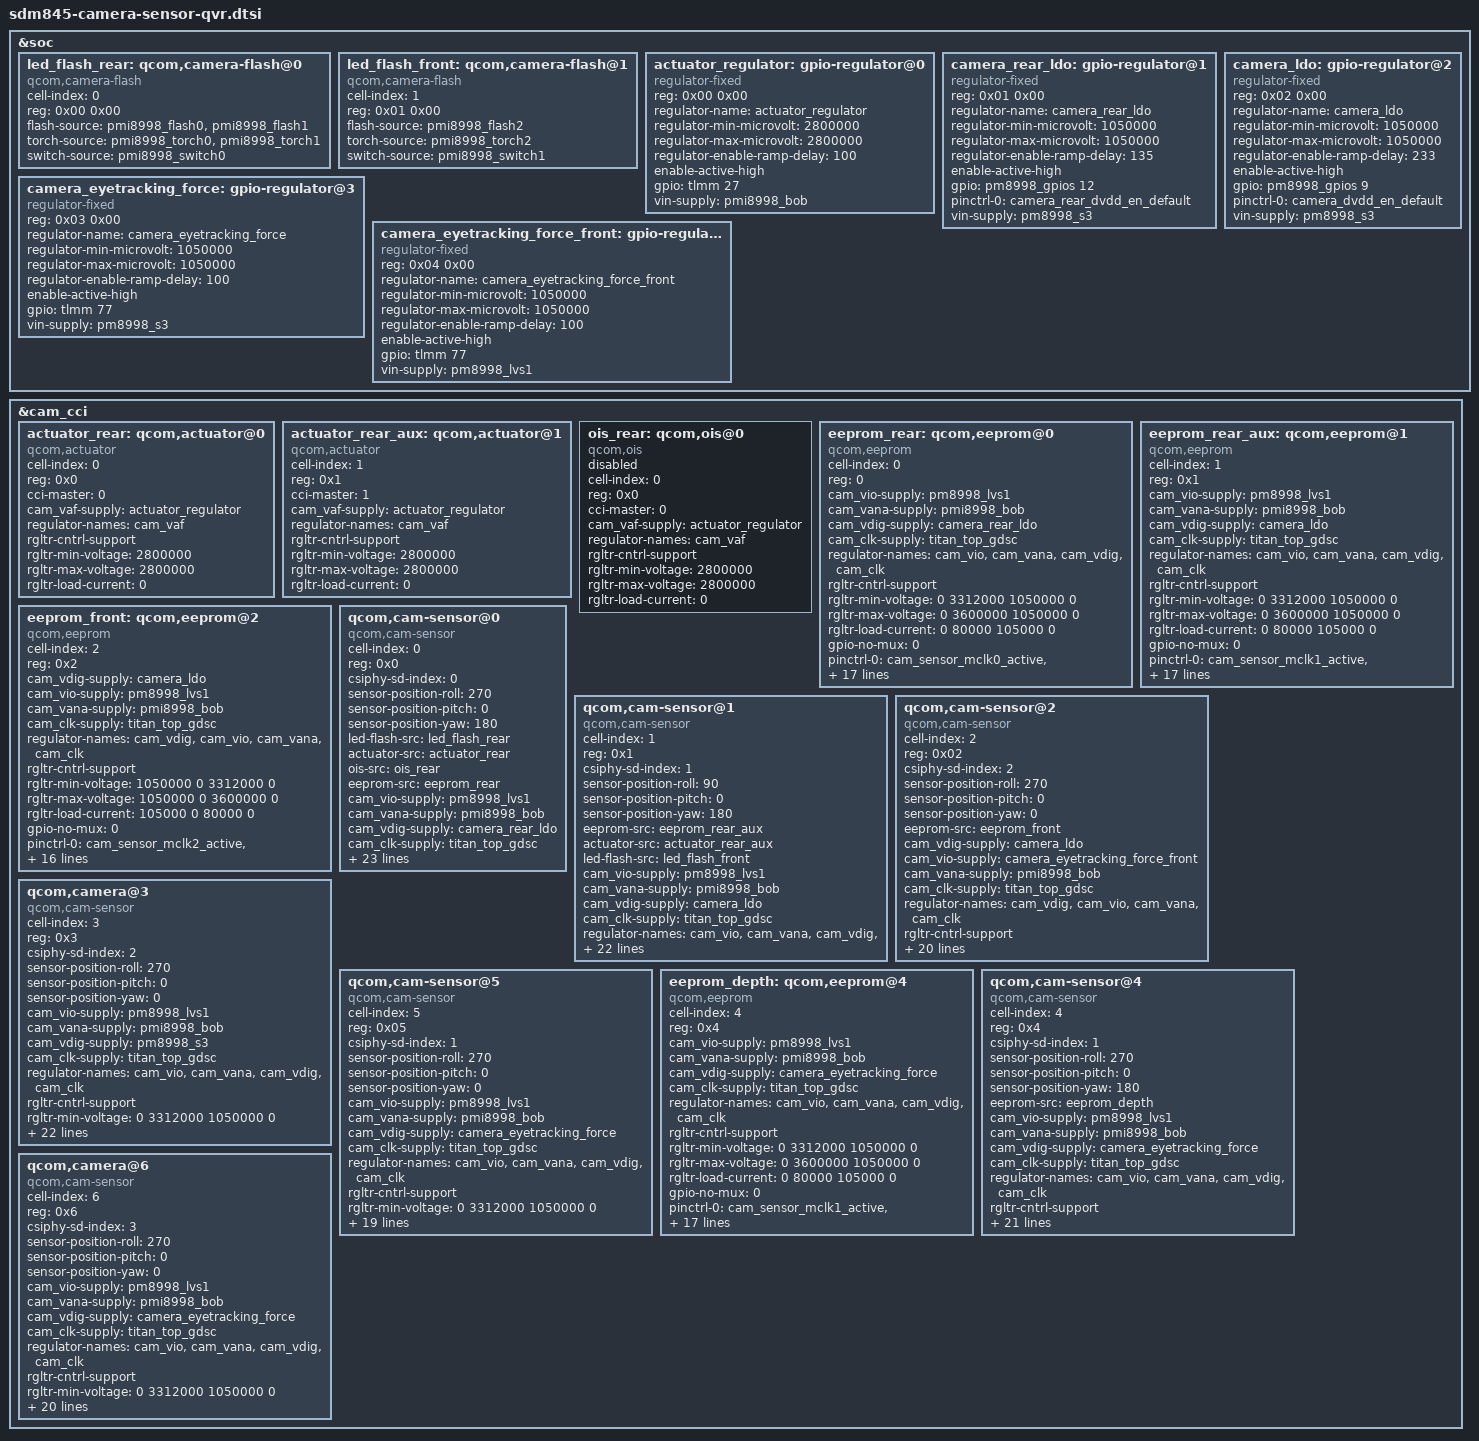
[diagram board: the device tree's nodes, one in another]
/*
 * Copyright (c) 2017-2018, The Linux Foundation. All rights reserved.
 *
 * This program is free software; you can redistribute it and/or modify
 * it under the terms of the GNU General Public License version 2 and
 * only version 2 as published by the Free Software Foundation.
 *
 * This program is distributed in the hope that it will be useful,
 * but WITHOUT ANY WARRANTY; without even the implied warranty of
 * MERCHANTABILITY or FITNESS FOR A PARTICULAR PURPOSE.  See the
 * GNU General Public License for more details.
 */

&soc {
	led_flash_rear: qcom,camera-flash@0 {
		cell-index = <0>;
		reg = <0x00 0x00>;
		compatible = "qcom,camera-flash";
		flash-source = <&pmi8998_flash0 &pmi8998_flash1>;
		torch-source = <&pmi8998_torch0 &pmi8998_torch1>;
		switch-source = <&pmi8998_switch0>;
		status = "ok";
	};

	led_flash_front: qcom,camera-flash@1 {
		cell-index = <1>;
		reg = <0x01 0x00>;
		compatible = "qcom,camera-flash";
		flash-source = <&pmi8998_flash2>;
		torch-source = <&pmi8998_torch2>;
		switch-source = <&pmi8998_switch1>;
		status = "ok";
	};

	actuator_regulator: gpio-regulator@0 {
		compatible = "regulator-fixed";
		reg = <0x00 0x00>;
		regulator-name = "actuator_regulator";
		regulator-min-microvolt = <2800000>;
		regulator-max-microvolt = <2800000>;
		regulator-enable-ramp-delay = <100>;
		enable-active-high;
		gpio = <&tlmm 27 0>;
		vin-supply = <&pmi8998_bob>;
	};

	camera_rear_ldo: gpio-regulator@1 {
		compatible = "regulator-fixed";
		reg = <0x01 0x00>;
		regulator-name = "camera_rear_ldo";
		regulator-min-microvolt = <1050000>;
		regulator-max-microvolt = <1050000>;
		regulator-enable-ramp-delay = <135>;
		enable-active-high;
		gpio = <&pm8998_gpios 12 0>;
		pinctrl-names = "default";
		pinctrl-0 = <&camera_rear_dvdd_en_default>;
		vin-supply = <&pm8998_s3>;
	};

	camera_ldo: gpio-regulator@2 {
		compatible = "regulator-fixed";
		reg = <0x02 0x00>;
		regulator-name = "camera_ldo";
		regulator-min-microvolt = <1050000>;
		regulator-max-microvolt = <1050000>;
		regulator-enable-ramp-delay = <233>;
		enable-active-high;
		gpio = <&pm8998_gpios 9 0>;
		pinctrl-names = "default";
		pinctrl-0 = <&camera_dvdd_en_default>;
		vin-supply = <&pm8998_s3>;
	};

	camera_eyetracking_force: gpio-regulator@3 {
		compatible = "regulator-fixed";
		reg = <0x03 0x00>;
		regulator-name = "camera_eyetracking_force";
		regulator-min-microvolt = <1050000>;
		regulator-max-microvolt = <1050000>;
		regulator-enable-ramp-delay = <100>;
		enable-active-high;
		gpio = <&tlmm 77 0>;
		vin-supply = <&pm8998_s3>;
	};

	camera_eyetracking_force_front: gpio-regulator@4 {
		compatible = "regulator-fixed";
		reg = <0x04 0x00>;
		regulator-name = "camera_eyetracking_force_front";
		regulator-min-microvolt = <1050000>;
		regulator-max-microvolt = <1050000>;
		regulator-enable-ramp-delay = <100>;
		enable-active-high;
		gpio = <&tlmm 77 0>;
		vin-supply = <&pm8998_lvs1>;
	};
};

&cam_cci {
	actuator_rear: qcom,actuator@0 {
		cell-index = <0>;
		reg = <0x0>;
		compatible = "qcom,actuator";
		cci-master = <0>;
		cam_vaf-supply = <&actuator_regulator>;
		regulator-names = "cam_vaf";
		rgltr-cntrl-support;
		rgltr-min-voltage = <2800000>;
		rgltr-max-voltage = <2800000>;
		rgltr-load-current = <0>;
	};

	actuator_rear_aux: qcom,actuator@1 {
		cell-index = <1>;
		reg = <0x1>;
		compatible = "qcom,actuator";
		cci-master = <1>;
		cam_vaf-supply = <&actuator_regulator>;
		regulator-names = "cam_vaf";
		rgltr-cntrl-support;
		rgltr-min-voltage = <2800000>;
		rgltr-max-voltage = <2800000>;
		rgltr-load-current = <0>;
	};

	ois_rear: qcom,ois@0 {
		cell-index = <0>;
		reg = <0x0>;
		compatible = "qcom,ois";
		cci-master = <0>;
		cam_vaf-supply = <&actuator_regulator>;
		regulator-names = "cam_vaf";
		rgltr-cntrl-support;
		rgltr-min-voltage = <2800000>;
		rgltr-max-voltage = <2800000>;
		rgltr-load-current = <0>;
		status = "disabled";
	};

	eeprom_rear: qcom,eeprom@0 {
		cell-index = <0>;
		reg = <0>;
		compatible = "qcom,eeprom";
		cam_vio-supply = <&pm8998_lvs1>;
		cam_vana-supply = <&pmi8998_bob>;
		cam_vdig-supply = <&camera_rear_ldo>;
		cam_clk-supply = <&titan_top_gdsc>;
		regulator-names = "cam_vio", "cam_vana", "cam_vdig",
			"cam_clk";
		rgltr-cntrl-support;
		rgltr-min-voltage = <0 3312000 1050000 0>;
		rgltr-max-voltage = <0 3600000 1050000 0>;
		rgltr-load-current = <0 80000 105000 0>;
		gpio-no-mux = <0>;
		pinctrl-names = "cam_default", "cam_suspend";
		pinctrl-0 = <&cam_sensor_mclk0_active
				&cam_sensor_rear_active>;
		pinctrl-1 = <&cam_sensor_mclk0_suspend
				&cam_sensor_rear_suspend>;
		gpios = <&tlmm 13 0>,
			<&tlmm 80 0>,
			<&tlmm 79 0>,
			<&tlmm 27 0>;
		gpio-reset = <1>;
		gpio-vana = <2>;
		gpio-vaf = <3>;
		gpio-req-tbl-num = <0 1 2 3>;
		gpio-req-tbl-flags = <1 0 0 0>;
		gpio-req-tbl-label = "CAMIF_MCLK0",
					"CAM_RESET0",
					"CAM_VANA0",
					"CAM_VAF";
		sensor-position = <0>;
		sensor-mode = <0>;
		cci-master = <0>;
		status = "ok";
		clocks = <&clock_camcc CAM_CC_MCLK0_CLK>;
		clock-names = "cam_clk";
		clock-cntl-level = "turbo";
		clock-rates = <24000000>;
	};

	eeprom_rear_aux: qcom,eeprom@1 {
		cell-index = <1>;
		reg = <0x1>;
		compatible = "qcom,eeprom";
		cam_vio-supply = <&pm8998_lvs1>;
		cam_vana-supply = <&pmi8998_bob>;
		cam_vdig-supply = <&camera_ldo>;
		cam_clk-supply = <&titan_top_gdsc>;
		regulator-names = "cam_vio", "cam_vana", "cam_vdig",
			"cam_clk";
		rgltr-cntrl-support;
		rgltr-min-voltage = <0 3312000 1050000 0>;
		rgltr-max-voltage = <0 3600000 1050000 0>;
		rgltr-load-current = <0 80000 105000 0>;
		gpio-no-mux = <0>;
		pinctrl-names = "cam_default", "cam_suspend";
		pinctrl-0 = <&cam_sensor_mclk1_active
				 &cam_sensor_front_active>;
		pinctrl-1 = <&cam_sensor_mclk1_suspend
				 &cam_sensor_front_suspend>;
		gpios = <&tlmm 14 0>,
			<&tlmm 28 0>,
			<&tlmm 8 0>,
			<&tlmm 27 0>;
		gpio-reset = <1>;
		gpio-vana = <2>;
		gpio-vaf = <3>;
		gpio-req-tbl-num = <0 1 2 3>;
		gpio-req-tbl-flags = <1 0 0 0>;
		gpio-req-tbl-label = "CAMIF_MCLK1",
					"CAM_RESET1",
					"CAM_VANA1",
					"CAM_VAF";
		sensor-position = <0>;
		sensor-mode = <0>;
		cci-master = <1>;
		status = "ok";
		clocks = <&clock_camcc CAM_CC_MCLK1_CLK>;
		clock-names = "cam_clk";
		clock-cntl-level = "turbo";
		clock-rates = <24000000>;
	};

	eeprom_front: qcom,eeprom@2 {
		cell-index = <2>;
		reg = <0x2>;
		compatible = "qcom,eeprom";
		cam_vdig-supply = <&camera_ldo>;
		cam_vio-supply = <&pm8998_lvs1>;
		cam_vana-supply = <&pmi8998_bob>;
		cam_clk-supply = <&titan_top_gdsc>;
		regulator-names = "cam_vdig", "cam_vio", "cam_vana",
			"cam_clk";
		rgltr-cntrl-support;
		rgltr-min-voltage = <1050000 0 3312000 0>;
		rgltr-max-voltage = <1050000 0 3600000 0>;
		rgltr-load-current = <105000 0 80000 0>;
		gpio-no-mux = <0>;
		pinctrl-names = "cam_default", "cam_suspend";
		pinctrl-0 = <&cam_sensor_mclk2_active
				 &cam_sensor_rear2_active>;
		pinctrl-1 = <&cam_sensor_mclk2_suspend
				 &cam_sensor_rear2_suspend>;
		gpios = <&tlmm 15 0>,
			<&tlmm 9 0>,
			<&tlmm 8 0>;
		gpio-reset = <1>;
		gpio-vana = <2>;
		gpio-req-tbl-num = <0 1 2>;
		gpio-req-tbl-flags = <1 0 0>;
		gpio-req-tbl-label = "CAMIF_MCLK2",
					"CAM_RESET2",
					"CAM_VANA2";
		sensor-position = <1>;
		sensor-mode = <0>;
		cci-master = <1>;
		status = "ok";
		clocks = <&clock_camcc CAM_CC_MCLK2_CLK>;
		clock-names = "cam_clk";
		clock-cntl-level = "turbo";
		clock-rates = <24000000>;
	};

	qcom,cam-sensor@0 {
		cell-index = <0>;
		compatible = "qcom,cam-sensor";
		reg = <0x0>;
		csiphy-sd-index = <0>;
		sensor-position-roll = <270>;
		sensor-position-pitch = <0>;
		sensor-position-yaw = <180>;
		led-flash-src = <&led_flash_rear>;
		actuator-src = <&actuator_rear>;
		ois-src = <&ois_rear>;
		eeprom-src = <&eeprom_rear>;
		cam_vio-supply = <&pm8998_lvs1>;
		cam_vana-supply = <&pmi8998_bob>;
		cam_vdig-supply = <&camera_rear_ldo>;
		cam_clk-supply = <&titan_top_gdsc>;
		regulator-names = "cam_vio", "cam_vana", "cam_vdig",
			"cam_clk";
		rgltr-cntrl-support;
		rgltr-min-voltage = <0 3312000 1050000 0>;
		rgltr-max-voltage = <0 3600000 1050000 0>;
		rgltr-load-current = <0 80000 105000 0>;
		gpio-no-mux = <0>;
		pinctrl-names = "cam_default", "cam_suspend";
		pinctrl-0 = <&cam_sensor_mclk0_active
				&cam_sensor_rear_active>;
		pinctrl-1 = <&cam_sensor_mclk0_suspend
				&cam_sensor_rear_suspend>;
		gpios = <&tlmm 13 0>,
			<&tlmm 80 0>,
			<&tlmm 79 0>;
		gpio-reset = <1>;
		gpio-vana = <2>;
		gpio-req-tbl-num = <0 1 2>;
		gpio-req-tbl-flags = <1 0 0>;
		gpio-req-tbl-label = "CAMIF_MCLK0",
					"CAM_RESET0",
					"CAM_VANA";
		sensor-mode = <0>;
		cci-master = <0>;
		status = "ok";
		clocks = <&clock_camcc CAM_CC_MCLK0_CLK>;
		clock-names = "cam_clk";
		clock-cntl-level = "turbo";
		clock-rates = <24000000>;
	};

	qcom,cam-sensor@1 {
		cell-index = <1>;
		compatible = "qcom,cam-sensor";
		reg = <0x1>;
		csiphy-sd-index = <1>;
		sensor-position-roll = <90>;
		sensor-position-pitch = <0>;
		sensor-position-yaw = <180>;
		eeprom-src = <&eeprom_rear_aux>;
		actuator-src = <&actuator_rear_aux>;
		led-flash-src = <&led_flash_front>;
		cam_vio-supply = <&pm8998_lvs1>;
		cam_vana-supply = <&pmi8998_bob>;
		cam_vdig-supply = <&camera_ldo>;
		cam_clk-supply = <&titan_top_gdsc>;
		regulator-names = "cam_vio", "cam_vana", "cam_vdig",
			"cam_clk";
		rgltr-cntrl-support;
		rgltr-min-voltage = <0 3312000 1050000 0>;
		rgltr-max-voltage = <0 3600000 1050000 0>;
		rgltr-load-current = <0 80000 105000 0>;
		gpio-no-mux = <0>;
		pinctrl-names = "cam_default", "cam_suspend";
		pinctrl-0 = <&cam_sensor_mclk1_active
				 &cam_sensor_front_active>;
		pinctrl-1 = <&cam_sensor_mclk1_suspend
				 &cam_sensor_front_suspend>;
		gpios = <&tlmm 14 0>,
			<&tlmm 28 0>,
			<&tlmm 8 0>;
		gpio-reset = <1>;
		gpio-vana = <2>;
		gpio-req-tbl-num = <0 1 2>;
		gpio-req-tbl-flags = <1 0 0>;
		gpio-req-tbl-label = "CAMIF_MCLK2",
					"CAM_RESET2",
					"CAM_VANA1";
		sensor-mode = <0>;
		cci-master = <1>;
		status = "ok";
		clocks = <&clock_camcc CAM_CC_MCLK1_CLK>;
		clock-names = "cam_clk";
		clock-cntl-level = "turbo";
		clock-rates = <24000000>;
	};

	qcom,cam-sensor@2 {
		cell-index = <2>;
		compatible = "qcom,cam-sensor";
		reg = <0x02>;
		csiphy-sd-index = <2>;
		sensor-position-roll = <270>;
		sensor-position-pitch = <0>;
		sensor-position-yaw = <0>;
		eeprom-src = <&eeprom_front>;
		cam_vdig-supply = <&camera_ldo>;
		cam_vio-supply = <&camera_eyetracking_force_front>;
		cam_vana-supply = <&pmi8998_bob>;
		cam_clk-supply = <&titan_top_gdsc>;
		regulator-names = "cam_vdig", "cam_vio", "cam_vana",
			"cam_clk";
		rgltr-cntrl-support;
		rgltr-min-voltage = <1050000 0 3312000 0>;
		rgltr-max-voltage = <1050000 0 3600000 0>;
		rgltr-load-current = <105000 0 80000 0>;
		gpio-no-mux = <0>;
		pinctrl-names = "cam_default", "cam_suspend";
		pinctrl-0 = <&cam_sensor_mclk2_active
				&cam_sensor_rear2_active>;
		pinctrl-1 = <&cam_sensor_mclk2_suspend
				&cam_sensor_rear2_suspend>;
		gpios = <&tlmm 15 0>,
			<&tlmm 9 0>,
			<&tlmm 8 0>;
		gpio-reset = <1>;
		gpio-vana = <2>;
		gpio-req-tbl-num = <0 1 2>;
		gpio-req-tbl-flags = <1 0 0>;
		gpio-req-tbl-label = "CAMIF_MCLK1",
					"CAM_RESET1",
					"CAM_VANA1";
		sensor-mode = <0>;
		cci-master = <1>;
		status = "ok";
		clocks = <&clock_camcc CAM_CC_MCLK2_CLK>;
		clock-names = "cam_clk";
		clock-cntl-level = "turbo";
		clock-rates = <24000000>;
	};

	qcom,camera@3 {
		cell-index = <3>;
		compatible = "qcom,cam-sensor";
		reg = <0x3>;
		csiphy-sd-index = <2>;
		sensor-position-roll = <270>;
		sensor-position-pitch = <0>;
		sensor-position-yaw = <0>;
		cam_vio-supply = <&pm8998_lvs1>;
		cam_vana-supply = <&pmi8998_bob>;
		cam_vdig-supply = <&pm8998_s3>;
		cam_clk-supply = <&titan_top_gdsc>;
		regulator-names = "cam_vio", "cam_vana", "cam_vdig",
					"cam_clk";
		rgltr-cntrl-support;
		rgltr-min-voltage = <0 3312000 1050000 0>;
		rgltr-max-voltage = <0 3600000 1050000 0>;
		rgltr-load-current = <0 80000 105000 0>;
		gpio-no-mux = <0>;
		pinctrl-names = "cam_default", "cam_suspend";
		pinctrl-0 = <&cam_sensor_mclk2_active
				&max_rst_active>;
		pinctrl-1 = <&cam_sensor_mclk2_suspend
				&max_rst_suspend>;
		gpios = <&tlmm 15 0>,
			<&tlmm 31 0>,
			<&tlmm 77 0>,
			<&tlmm 78 0>,
			<&tlmm 32 0>;
		gpio-reset = <1>;
		gpio-vana = <2>;
		gpio-custom1 = <3>;
		gpio-custom2 = <4>;
		gpio-req-tbl-num = <0 1 2 3 4>;
		gpio-req-tbl-flags = <1 0 0 0 0>;
		gpio-req-tbl-label = "CAMIF_MCLK2",
					"CAM_RESET2",
					"CAM_VANA2",
					"CAM_CUSTOM1",
					"CAM_CUSTOM2";
		sensor-mode = <0>;
		cci-master = <1>;
		status = "ok";
		clocks = <&clock_camcc CAM_CC_MCLK2_CLK>;
		clock-names = "cam_clk";
		clock-cntl-level = "turbo";
		clock-rates = <24000000>;
	};

	qcom,cam-sensor@5 {
		cell-index = <5>;
		compatible = "qcom,cam-sensor";
		reg = <0x05>;
		csiphy-sd-index = <1>;
		sensor-position-roll = <270>;
		sensor-position-pitch = <0>;
		sensor-position-yaw = <0>;
		cam_vio-supply = <&pm8998_lvs1>;
		cam_vana-supply = <&pmi8998_bob>;
		cam_vdig-supply = <&camera_eyetracking_force>;
		cam_clk-supply = <&titan_top_gdsc>;
		regulator-names = "cam_vio", "cam_vana", "cam_vdig",
			"cam_clk";
		rgltr-cntrl-support;
		rgltr-min-voltage = <0 3312000 1050000 0>;
		rgltr-max-voltage = <0 3600000 1050000 0>;
		rgltr-load-current = <0 80000 105000 0>;
		gpio-no-mux = <0>;
		pinctrl-names = "cam_default", "cam_suspend";
		pinctrl-0 = <&cam_sensor_mclk1_active
				 &cam_sensor_fisheye_active>;
		pinctrl-1 = <&cam_sensor_mclk1_suspend
				 &cam_sensor_fisheye_suspend>;
		gpios = <&tlmm 14 0>,
			<&tlmm 76 0>,
			<&tlmm 75 0>;
		gpio-reset = <1>;
		gpio-vana = <2>;
		gpio-req-tbl-num = <0 1 2>;
		gpio-req-tbl-flags = <1 0 0>;
		gpio-req-tbl-label = "CAMIF_MCLK1",
					"CAM_RESET1",
					"CAM_VANA1";
		sensor-mode = <0>;
		cci-master = <1>;
		status = "ok";
		clocks = <&clock_camcc CAM_CC_MCLK1_CLK>;
		clock-names = "cam_clk";
		clock-cntl-level = "turbo";
		clock-rates = <24000000>;
	};

	eeprom_depth: qcom,eeprom@4 {
		cell-index = <4>;
		reg = <0x4>;
		compatible = "qcom,eeprom";
		cam_vio-supply = <&pm8998_lvs1>; /* checked, MTP845 */
		cam_vana-supply = <&pmi8998_bob>;
		cam_vdig-supply = <&camera_eyetracking_force>;
		cam_clk-supply = <&titan_top_gdsc>;
		regulator-names = "cam_vio", "cam_vana", "cam_vdig", "cam_clk";
		rgltr-cntrl-support;
		rgltr-min-voltage = <0 3312000 1050000 0>;
		rgltr-max-voltage = <0 3600000 1050000 0>;
		rgltr-load-current = <0 80000 105000 0>;
		gpio-no-mux = <0>;
		pinctrl-names = "cam_default", "cam_suspend";
		pinctrl-0 = <&cam_sensor_mclk1_active
				&cam_sensor_depth_active>;
		pinctrl-1 = <&cam_sensor_mclk1_suspend
				&cam_sensor_depth_suspend>;
		gpios = <&tlmm 14 0>,
			<&tlmm 28 0>,
			<&tlmm 23 0>,
			<&tlmm 24 0>;
		gpio-reset = <1>;   //RESET
		gpio-vana = <2>;
		gpio-vdig = <3>;
		gpio-req-tbl-num = <0 1 2 3> ;
		gpio-req-tbl-flags = <1 0 0 0>;
		gpio-req-tbl-label = "CAMIF_MCLK1",
					"CAM_RESET1",
					"CAM_VANA1",
					"CAM_VDIG1";
		sensor-position = <0>;
		sensor-mode = <0>;
		cci-master = <1>;
		status = "ok";
		clocks = <&clock_camcc CAM_CC_MCLK1_CLK>;
		clock-names = "cam_clk";
		clock-cntl-level = "turbo";
		clock-rates = <24000000>;
	};

	qcom,cam-sensor@4 {
		cell-index = <4>;
		compatible = "qcom,cam-sensor";
		reg = <0x4>;
		csiphy-sd-index = <1>;
		sensor-position-roll = <270>; /* checked, MTP845 */
		sensor-position-pitch = <0>; /* checked, MTP845 */
		sensor-position-yaw = <180>; /* checked, MTP845 */
		eeprom-src = <&eeprom_depth>;
		cam_vio-supply = <&pm8998_lvs1>; /* checked, MTP845 */
		cam_vana-supply = <&pmi8998_bob>;
		cam_vdig-supply = <&camera_eyetracking_force>;
		cam_clk-supply = <&titan_top_gdsc>;
		regulator-names = "cam_vio", "cam_vana", "cam_vdig", "cam_clk";
		rgltr-cntrl-support;
		rgltr-min-voltage = <0 3312000 1050000 0>;
		rgltr-max-voltage = <0 3600000 1050000 0>;
		rgltr-load-current = <0 80000 105000 0>;
		gpio-no-mux = <0>;
		pinctrl-names = "cam_default", "cam_suspend";
		pinctrl-0 = <&cam_sensor_mclk1_active
				&cam_sensor_depth_active>;
		pinctrl-1 = <&cam_sensor_mclk1_suspend
				&cam_sensor_depth_suspend>;
		gpios = <&tlmm 14 0>, //MCLK1
			    <&tlmm 28 0>, //RESET
			    <&tlmm 23 0>, //vana
			    <&tlmm 24 0>;
		gpio-reset = <1>;   //RESET
		gpio-vana = <2>;
		gpio-vdig = <3>;
		gpio-req-tbl-num = <0 1 2 3> ;
		gpio-req-tbl-flags = <1 0 0 0>;
		gpio-req-tbl-label = "CAMIF_MCLK1",
					"CAM_RESET1",
					"CAM_VANA1",
					"CAM_VDIG1";
		sensor-mode = <0>; // 0 -> back camera 2D
		cci-master = <1>; /* checked, MTP845 we are on I2C 0 */
		status = "ok";
		clocks = <&clock_camcc CAM_CC_MCLK1_CLK>;
		clock-names = "cam_clk";
		clock-cntl-level = "turbo";
		clock-rates = <24000000>;
	};

	qcom,camera@6 {
		cell-index = <6>;
		compatible = "qcom,cam-sensor";
		reg = <0x6>;
		csiphy-sd-index = <3>;
		sensor-position-roll = <270>;
		sensor-position-pitch = <0>;
		sensor-position-yaw = <0>;
		cam_vio-supply = <&pm8998_lvs1>;
		cam_vana-supply = <&pmi8998_bob>;
		cam_vdig-supply = <&camera_eyetracking_force>;
		cam_clk-supply = <&titan_top_gdsc>;
		regulator-names = "cam_vio", "cam_vana", "cam_vdig",
					"cam_clk";
		rgltr-cntrl-support;
		rgltr-min-voltage = <0 3312000 1050000 0>;
		rgltr-max-voltage = <0 3600000 1050000 0>;
		rgltr-load-current = <0 80000 105000 0>;
		gpio-no-mux = <0>;
		pinctrl-names = "cam_default", "cam_suspend";
		pinctrl-0 = <&cam_sensor_mclk3_active
				&max_6dof_active>;
		pinctrl-1 = <&cam_sensor_mclk3_suspend
				&max_6dof_suspend>;
		gpios = <&tlmm 16 0>,
			<&tlmm 30 0>,
			<&tlmm 95 0>,
			<&tlmm 94 0>;
		gpio-reset = <1>;
		gpio-vana = <2>;
		gpio-vdig = <3>;
		gpio-req-tbl-num = <0 1 2 3 >;
		gpio-req-tbl-flags = <1 0 0 0>;
		gpio-req-tbl-label = "CAMIF_MCLK3",
					"CAM_RESET3",
					"CAM_VANA3",
					"CAM_VDIG3" ;
		sensor-mode = <0>;
		cci-master = <0>;
		status = "ok";
		clocks = <&clock_camcc CAM_CC_MCLK3_CLK>;
		clock-names = "cam_clk";
		clock-cntl-level = "turbo";
		clock-rates = <24000000>;
	};
};
